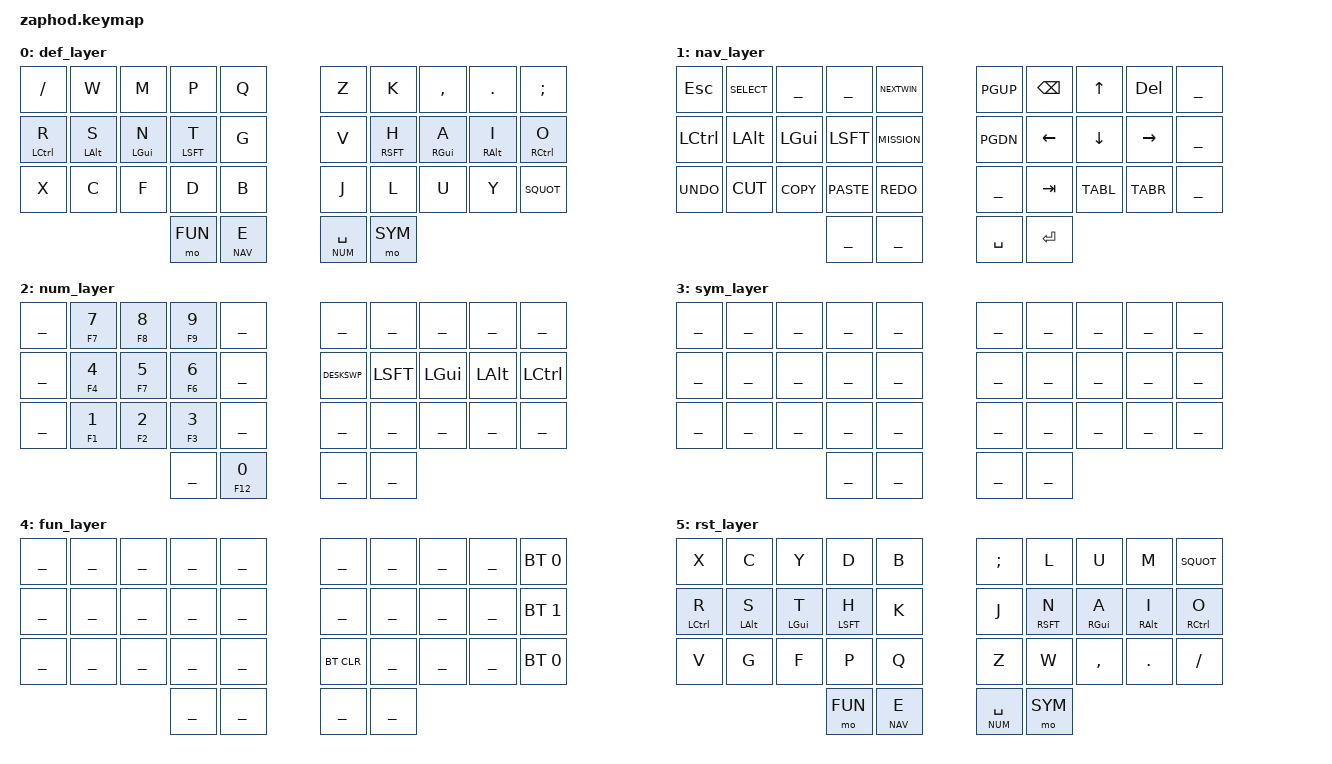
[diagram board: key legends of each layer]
/*
 * Copyright (c) 2021 Pete Johanson
 *
 * SPDX-License-Identifier: MIT
 */

#include <behaviors.dtsi>
#include <dt-bindings/zmk/keys.h>
#include <dt-bindings/zmk/bt.h>

#include "./helpers.h"
#include "./keycodes.h"

#define STICKY_KEY_TIMEOUT 60000

#define DEF 0
#define NAV 1
#define NUM 2
#define SYM 3
#define FUN 4
#define RST 5


/**
 * Sticky key that does not time out rapidly
 * Useful for simulating one-shot shift 
 */
ZMK_BEHAVIOR(stk, sticky_key,
  quick-release;
  release-after-ms = <STICKY_KEY_TIMEOUT>;
  bindings = <&kp>;
)

/**
 * Sticky key on tap, normal key on hold
 * Useful for modifier-clicking without the modifier remaining active
 */
ZMK_BEHAVIOR(tp, hold_tap,
  tapping_term_ms = <200>;
  flavor = "tap-preferred";
  bindings = <&kp>, <&sk>;
)
#define TP(KEY) &tp KEY KEY 

/**
 * Home-row Mods 
 * Inspired by Apsu's comment on using HRMS with tap-preferred, suited for fast typing / rolling
 * https://discord.com/channels/714176584269168732/846328975570763806/1010577529297457214
 */
ZMK_BEHAVIOR(hm, hold_tap,
  flavor = "tap-preferred";
  tapping-term-ms = <250>;
  quick-tap-ms = <250>;
  // global-quick-tap;
  bindings = <&kp>, <&kp>;
)

/**
 * "Auto-Shift" but used for FKeys on numbers
 */
ZMK_BEHAVIOR(as, hold_tap,
  flavor = "tap-preferred";
  tapping-term-ms = <130>;
  quick-tap-ms = <0>;
  bindings = <&kp>, <&kp>;
)

/**
 * Enable quick double-tap-holds on lt keys for key repeat
 */
&lt { quick_tap_ms = <200>; };

/**
 * This is a variant of AptX mak mod based on
 * https://github.com/Apsu/zmk-luna/blob/main/config/luna.keymap
 */
ZMK_LAYER(def_layer,
// ╭─────────────┬─────────────┬─────────────┬─────────────┬─────────────╮   ╭─────────────┬─────────────┬─────────────┬─────────────┬─────────────╮
     &kp SLASH     &kp W         &kp M         &kp P         &kp Q             &kp Z         &kp K         &kp COMMA     &kp DOT       &kp SEMI
// ├─────────────┼─────────────┼─────────────┼─────────────┼─────────────┤   ├─────────────┼─────────────┼─────────────┼─────────────┼─────────────┤
     &hm LCTL R    &hm LALT S    &hm LGUI N    &hm LSFT T    &kp G             &kp V         &hm RSFT H    &hm RGUI A    &hm RALT I    &hm RCTL O 
// ├─────────────┼─────────────┼─────────────┼─────────────┼─────────────┤   ├─────────────┼─────────────┼─────────────┼─────────────┼─────────────┤
     &kp X         &kp C         &kp F         &kp D         &kp B             &kp J         &kp L         &kp U         &kp Y         &kp SQUOT 
// ╰─────────────┴─────────────┴─────────────┼─────────────┼─────────────┤   ├─────────────┼─────────────┼─────────────┴─────────────┴─────────────╯
                                               &mo FUN       &lt NAV E         &lt NUM SPC   &mo SYM
//                                           ╰─────────────┴─────────────╯   ╰─────────────┴─────────────╯ 
)

/**
 * 
 */
ZMK_LAYER(nav_layer,
// ╭─────────────┬─────────────┬─────────────┬─────────────┬─────────────╮   ╭─────────────┬─────────────┬─────────────┬─────────────┬─────────────╮
     &kp ESC       &kp SELECT    ___________   ___________   &kp NEXTWIN       &kp PGUP      &kp BSPC      &kp UP        &kp DELETE    ___________ 
// ├─────────────┼─────────────┼─────────────┼─────────────┼─────────────┤   ├─────────────┼─────────────┼─────────────┼─────────────┼─────────────┤
     &kp LCTL      &kp LALT      &kp LGUI      &kp LSFT      &kp MISSION       &kp PGDN      &kp LEFT      &kp DOWN      &kp RIGHT     ___________ 
// ├─────────────┼─────────────┼─────────────┼─────────────┼─────────────┤   ├─────────────┼─────────────┼─────────────┼─────────────┼─────────────┤
     &kp UNDO      &kp CUT       &kp COPY      &kp PASTE     &kp REDO          ___________   &kp TAB       &kp TABL      &kp TABR      ___________ 
// ╰─────────────┴─────────────┴─────────────┼─────────────┼─────────────┤   ├─────────────┼─────────────┼─────────────┴─────────────┴─────────────╯
                                               ___________   ___________       &kp SPACE     &kp ENTER
//                                           ╰─────────────┴─────────────╯   ╰─────────────┴─────────────╯ 
)

/**
 * 
 */
ZMK_LAYER(num_layer,
// ╭─────────────┬─────────────┬─────────────┬─────────────┬─────────────╮   ╭─────────────┬─────────────┬─────────────┬─────────────┬─────────────╮
     ___________   &as F7 N7     &as F8 N8     &as F9 N9     ___________       ___________   ___________   ___________   ___________   ___________ 
// ├─────────────┼─────────────┼─────────────┼─────────────┼─────────────┤   ├─────────────┼─────────────┼─────────────┼─────────────┼─────────────┤
     ___________   &as F4 N4     &as F7 N5     &as F6 N6     ___________       &kp DESKSWP   &kp LSFT      &kp LGUI      &kp LALT      &kp LCTL 
// ├─────────────┼─────────────┼─────────────┼─────────────┼─────────────┤   ├─────────────┼─────────────┼─────────────┼─────────────┼─────────────┤
     ___________   &as F1 N1     &as F2 N2     &as F3 N3     ___________       ___________   ___________   ___________   ___________   ___________ 
// ╰─────────────┴─────────────┴─────────────┼─────────────┼─────────────┤   ├─────────────┼─────────────┼─────────────┴─────────────┴─────────────╯
                                               ___________   &as F12 N0        ___________   ___________
//                                           ╰─────────────┴─────────────╯   ╰─────────────┴─────────────╯ 
)

/**
 * 
 */
ZMK_LAYER(sym_layer,
// ╭─────────────┬─────────────┬─────────────┬─────────────┬─────────────╮   ╭─────────────┬─────────────┬─────────────┬─────────────┬─────────────╮
     ___________   ___________   ___________   ___________   ___________       ___________   ___________   ___________   ___________   ___________ 
// ├─────────────┼─────────────┼─────────────┼─────────────┼─────────────┤   ├─────────────┼─────────────┼─────────────┼─────────────┼─────────────┤
     ___________   ___________   ___________   ___________   ___________       ___________   ___________   ___________   ___________   ___________ 
// ├─────────────┼─────────────┼─────────────┼─────────────┼─────────────┤   ├─────────────┼─────────────┼─────────────┼─────────────┼─────────────┤
     ___________   ___________   ___________   ___________   ___________       ___________   ___________   ___________   ___________   ___________ 
// ╰─────────────┴─────────────┴─────────────┼─────────────┼─────────────┤   ├─────────────┼─────────────┼─────────────┴─────────────┴─────────────╯
                                               ___________   ___________       ___________   ___________
//                                           ╰─────────────┴─────────────╯   ╰─────────────┴─────────────╯ 
)

/**
 * 
 */
ZMK_LAYER(fun_layer,
// ╭─────────────┬─────────────┬─────────────┬─────────────┬─────────────╮   ╭─────────────┬─────────────┬─────────────┬─────────────┬─────────────╮
     ___________   ___________   ___________   ___________   ___________       ___________   ___________   ___________   ___________   &bt BT_SEL 0
// ├─────────────┼─────────────┼─────────────┼─────────────┼─────────────┤   ├─────────────┼─────────────┼─────────────┼─────────────┼─────────────┤
     ___________   ___________   ___________   ___________   ___________       ___________   ___________   ___________   ___________   &bt BT_SEL 1
// ├─────────────┼─────────────┼─────────────┼─────────────┼─────────────┤   ├─────────────┼─────────────┼─────────────┼─────────────┼─────────────┤
     ___________   ___________   ___________   ___________   ___________       &bt BT_CLR    ___________   ___________   ___________   &bt BT_SEL 0
// ╰─────────────┴─────────────┴─────────────┼─────────────┼─────────────┤   ├─────────────┼─────────────┼─────────────┴─────────────┴─────────────╯
                                               ___________   ___________       ___________   ___________
//                                           ╰─────────────┴─────────────╯   ╰─────────────┴─────────────╯ 
)


/**
 * This is a variant of AptHD based on
 * https://github.com/Apsu/APTHD
 */
ZMK_LAYER(rst_layer,
// ╭─────────────┬─────────────┬─────────────┬─────────────┬─────────────╮   ╭─────────────┬─────────────┬─────────────┬─────────────┬─────────────╮
     &kp X         &kp C         &kp Y         &kp D         &kp B             &kp SEMI      &kp L         &kp U         &kp M         &kp SQUOT
// ├─────────────┼─────────────┼─────────────┼─────────────┼─────────────┤   ├─────────────┼─────────────┼─────────────┼─────────────┼─────────────┤
     &hm LCTL R    &hm LALT S    &hm LGUI T    &hm LSFT H    &kp K             &kp J         &hm RSFT N    &hm RGUI A    &hm RALT I    &hm RCTL O 
// ├─────────────┼─────────────┼─────────────┼─────────────┼─────────────┤   ├─────────────┼─────────────┼─────────────┼─────────────┼─────────────┤
     &kp V         &kp G         &kp F         &kp P         &kp Q             &kp Z         &kp W         &kp COMMA     &kp DOT       &kp SLASH 
// ╰─────────────┴─────────────┴─────────────┼─────────────┼─────────────┤   ├─────────────┼─────────────┼─────────────┴─────────────┴─────────────╯
                                               &mo FUN       &lt NAV E         &lt NUM SPC   &mo SYM
//                                           ╰─────────────┴─────────────╯   ╰─────────────┴─────────────╯ 
)




/*                KEY POSITIONS

  ╭────────────────────╮ ╭────────────────────╮
  │  0   1   2   3   4 │ │  5   6   7   8   9 │
  │ 10  11  12  13  14 │ │ 15  16  17  18  19 │ 
  │ 20  21  22  23  24 │ │ 25  26  27  28  29 │
  ╰───────────╮ 30  31 │ │ 32  33 ╭───────────╯
              ╰────────╯ ╰────────╯
*/


ZMK_COMBO(caps_word, &caps_word, 30 33, DEF)
ZMK_COMBO(tog_rst, &tog RST, 0 9, DEF RST)


/**
 * Used for having a repeat key on a layer key
ZMK_BEHAVIOR(mr, hold_tap,
  tapping_term_ms = <200>;
  flavor = "tap-preferred";
  bindings = <&mo>, <&key_repeat>;
)
#define MR(LAYER) &mr LAYER 0
 */


/**
// ╭─────────────┬─────────────┬─────────────┬─────────────┬─────────────╮   ╭─────────────┬─────────────┬─────────────┬─────────────┬─────────────╮
     ___________   ___________   ___________   ___________   ___________       ___________   ___________   ___________   ___________   ___________ 
// ├─────────────┼─────────────┼─────────────┼─────────────┼─────────────┤   ├─────────────┼─────────────┼─────────────┼─────────────┼─────────────┤
     ___________   ___________   ___________   ___________   ___________       ___________   ___________   ___________   ___________   ___________ 
// ├─────────────┼─────────────┼─────────────┼─────────────┼─────────────┤   ├─────────────┼─────────────┼─────────────┼─────────────┼─────────────┤
     ___________   ___________   ___________   ___________   ___________       ___________   ___________   ___________   ___________   ___________ 
// ╰─────────────┴─────────────┴─────────────┼─────────────┼─────────────┤   ├─────────────┼─────────────┼─────────────┴─────────────┴─────────────╯
                                               ___________   ___________       ___________   ___________
//                                           ╰─────────────┴─────────────╯   ╰─────────────┴─────────────╯ 
**/
